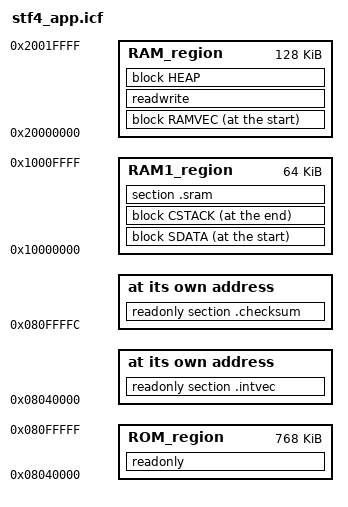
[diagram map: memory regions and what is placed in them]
/*###ICF### Section handled by ICF editor, don't touch! ****/
/*-Editor annotation file-*/
/* IcfEditorFile="$TOOLKIT_DIR$\config\ide\IcfEditor\cortex_v1_0.xml" */
/*-Specials-*/
define symbol __ICFEDIT_intvec_start__ = 0x08040000;
/*-Memory Regions-*/
define symbol __ICFEDIT_region_ROM_start__ = 0x08040000;
define symbol __ICFEDIT_region_ROM_end__   = 0x080FFFFF;
define symbol __ICFEDIT_region_RAM_start__ = 0x20000000;
define symbol __ICFEDIT_region_RAM_end__   = 0x2001FFFF;
/*-Sizes-*/
define symbol __ICFEDIT_size_cstack__ = 0x1000;
define symbol __ICFEDIT_size_heap__   = 0x0000;
/**** End of ICF editor section. ###ICF###*/

define symbol __checksum_start__    = 0x080FFFFC;

define symbol __region_RAM1_start__ = 0x10000000;
define symbol __region_RAM1_end__   = 0x1000FFFF;

define symbol __size_intvec__           = 0x00000440;
define symbol __SData_size__            = 0x00000100;

define memory mem with size = 4G;
define region ROM_region  = mem:[from (__ICFEDIT_region_ROM_start__)  to __ICFEDIT_region_ROM_end__];
define region RAM_region  = mem:[from __ICFEDIT_region_RAM_start__ to __ICFEDIT_region_RAM_end__];
define region RAM1_region = mem:[from __region_RAM1_start__   to __region_RAM1_end__];

define block CSTACK    with alignment = 8, size = __ICFEDIT_size_cstack__   { };
define block HEAP      with alignment = 8, size = __ICFEDIT_size_heap__     { };
define block RAMVEC    with alignment = 8, size = __size_intvec__           { };
define block SDATA     with alignment = 8, size = __SData_size__            { };

/* initialize by copy { readwrite }; */
/* do not initialize  { section .noinit }; */
do not initialize  { section .noinit, readonly section .intvec, section .sdata };
//initialize by copy { readwrite, readonly }
//            except { readonly section .intvec, readonly section .checksum, object iar_stf4_cstartup.o, object system_stm32f4xx.o};
initialize by copy { readwrite };
place at address   mem:__checksum_start__       { readonly section .checksum};
place at address   mem:__ICFEDIT_intvec_start__ { readonly section .intvec };
place at start of RAM1_region                   { block SDATA };
place at start of RAM_region                    { block RAMVEC };
place at end of   RAM1_region                   { block CSTACK };

place in          ROM_region                    { readonly };
place in          RAM_region                    { readwrite, block HEAP };
place in RAM1_region  { section .sram };

keep { block SDATA, readonly section .checksum };

define exported symbol __cstack_end__   = end(RAM1_region) + 1;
